# M2354 register map
File version: 1.0
Registers are 32-bit, read-write, reset 0x0 unless marked. A register's access mark holds for its fields unless they carry their own. Offsets are from the block's base; [hi:lo] are bit positions.

## SCS — SYST_SCR Register Map
Base 0xE000E000
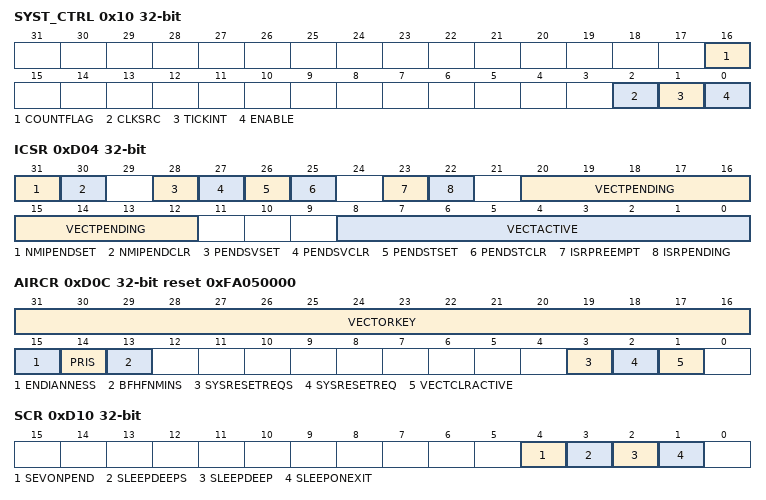
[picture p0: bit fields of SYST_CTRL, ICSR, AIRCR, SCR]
0x10 SYST_CTRL — SysTick Control and Status Register
  [16] COUNTFLAG — System Tick Counter Flag. Returns 1 if timer counted to 0 since last time this register was read. COUNTFLAG is set by a count transition from 1 to 0. COUNTFLAG is cleared on read or by a write to the Current Value register.
  [2] CLKSRC — System Tick Clock Source Selection
    0=Clock source is the (optional) external reference clock; 1=Core clock used for SysTick
  [1] TICKINT — System Tick Interrupt Enabled
    0=Counting down to 0 does not cause the SysTick exception to be pended. Software can use COUNTFLAG to determine if a count to zero has occurred; 1=Counting down to 0 will cause the SysTick exception to be pended. Clearing the SysTick current value register by a register write in software will not cause SysTick to be pended
  [0] ENABLE — System Tick Counter Enabled
    0=Counter Disabled; 1=Counter will operate in a multi-shot manner
0x14 SYST_LOAD reset not defined — SysTick Reload Value Register
  [23:0] RELOAD — System Tick Reload Value. Value to load into the Current Value register when the counter reaches 0.
0x18 SYST_VAL reset not defined — SysTick Current Value Register
  [23:0] CURRENT — System Tick Current Value. Current counter value. This is the value of the counter at the time it is sampled. The counter does not provide read-modify-write protection. The register is write-clear. A software write of any value will clear the register to 0. Unsupported bits RAZ.
0xD04 ICSR — Interrupt Control and State Register
  [31] NMIPENDSET — NMI Set-pending Bit. Write Operation: Note: If AIRCR.BFHFNMINS is 0, this bit is RAZ/WI from Non-secure state.
    0=No effect. NMI exception is not pending; 1=Changes NMI exception state to pending. NMI exception is pending
  [30] NMIPENDCLR — NMI Bit-pending Bit. Note: If AIRCR.BFHFNMINS is 0, this bit is RAZ/WI from Non-secure state.
    0=No effect; 1=Clear pending status
  [28] PENDSVSET — PendSV Set-pending Bit. Write Operation: Note: Writing 1 to this bit is the only way to set the PendSV exception state to pending.
    0=No effect. PendSV exception is not pending; 1=Changes PendSV exception state to pending. PendSV exception is pending
  [27] PENDSVCLR — PendSV Clear-pending Bit. Write Operation: Note: This is a write only bit. To clear the PENDSV bit, you must 'write 0 to PENDSVSET and write 1 to PENDSVCLR' at the same time.
    0=No effect; 1=Removes the pending state from the PendSV exception
  [26] PENDSTSET — SysTick Exception Set-pending Bit. Write Operation:
    0=No effect. SysTick exception is not pending; 1=Changes SysTick exception state to pending. SysTick exception is pending
  [25] PENDSTCLR — SysTick Exception Clear-pending Bit. Write Operation: Note: This is a write only bit. To clear the PENDST bit, you must 'write 0 to PENDSTSET and write 1 to PENDSTCLR' at the same time.
    0=No effect; 1=Removes the pending state from the SysTick exception
  [23] ISRPREEMPT ro — Interrupt Preempt Bit (Read Only). If set, a pending exception will be serviced on exit from the debug halt state.
  [22] ISRPENDING ro — Interrupt Pending Flag, Excluding NMI and Faults (Read Only)
    0=Interrupt not pending; 1=Interrupt pending
  [20:12] VECTPENDING — Number of the Highest Pended Exception
    0=no pending exceptions
  [8:0] VECTACTIVE — Number of the Current Active Exception
    0=Thread mode
0xD08 VTOR — Vector Table Offset Register
  [31:9] TBLOFF — Table Offset Bits. The vector table address for the selected Security state.
0xD0C AIRCR reset 0xFA050000 — Application Interrupt and Reset Control Register
  [31:16] VECTORKEY — Register Access Key. When writing this register, this field should be 0x05FA, otherwise the write action will be ignored. The VECTORKEY filed is used to prevent accidental write to this register from resetting the system or clearing of the exception status.
  [15] ENDIANNESS — Data Endianness
    0=Little-endian; 1=Big-endian
  [14] PRIS — Priority Secure Exceptions Bit
    0=Priority ranges of Secure and Non-secure exceptions are identical.1 = Non-secure exceptions are de-prioritized
  [13] BFHFNMINS — BusFault, HardFault, AndNMI Non-secure Enable Bit
    0=BusFault, HardFault, and NMI are Secure.1 = BusFault, Non-secure HardFault and NMI are Non-secure and exceptions can target Non-secure HardFault (Priority = -3) while Secure HardFault is secure and exception targets secure HardFault (Priority = -3)
  [3] SYSRESETREQS — System Reset Request Secure Only Bit
    0=SYSRESETREQ functionality is available to both security states.1 = SYSRESETREQ functionality is available to secure state only
  [2] SYSRESETREQ — System Reset Request Bit. Writing This Bit to 1 Will Cause A Reset Signal To Be Asserted To The Chip And Indicate A Reset Is Requested. This bit is write only and self-cleared as part of the reset sequence.
  [1] VECTCLRACTIVE — Exception Active Status Clear Bit. Setting This Bit To 1 Will Clears All Active State Information For Fixed And Configurable Exceptions. This bit is write only and can only be written when the core is halted. Note: It is the debugger's responsibility to re-initialize the stack.
0xD10 SCR — System Control Register
  [4] SEVONPEND — Send Event on Pending. When an event or interrupt enters pending state, the event signal wakes up the processor from WFE. If the processor is not waiting for an event, the event is registered and affects the next WFE. The processor also wakes up on execution of an SEV instruction or an external event.
    0=Only enabled interrupts or events can wake up the processor, while disabled interrupts are excluded; 1=Enabled events and all interrupts, including disabled interrupts, can wake up the processor
  [3] SLEEPDEEPS — SLEEPDEEP Bit Accessible Selection. Control whether the SLEEPDEEP bit is only accessible from the Secure state.
    0=The SLEEPDEEP bit is accessible from both security states; 1=The SLEEPDEEP bit behaves as RAZ/WI when accessed from the Non-secure state
  [2] SLEEPDEEP — Processor Deep Sleep and Sleep Mode Selection. Control Whether the Processor Uses Sleep Or Deep Sleep as its Low Power Mode.
    0=Sleep; 1=Deep sleep
  [1] SLEEPONEXIT — Sleep-on-exit Enable Control. This bit indicate Sleep-On-Exit when Returning from Handler Mode to Thread Mode. Setting this bit to 1 enables an interrupt driven application to avoid returning to an empty main application.
    0=Do not sleep when returning to Thread mode; 1=Enters sleep, or deep sleep, on return from an ISR to Thread mode
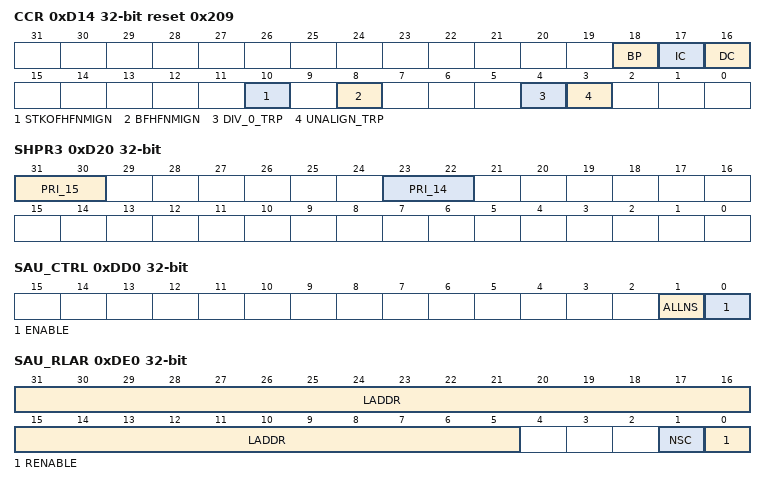
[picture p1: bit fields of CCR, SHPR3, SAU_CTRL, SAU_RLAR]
0xD14 CCR reset 0x209 — Configuration and Control Register
  [18] BP — Branch Prediction Enable Bit. This bit is RAZ/WI.
  [17] IC — Instruction Cache Enable Bit. This bit is RAZ/WI.
  [16] DC — Data Cache Enable Bit. This bit is RAZ/WI.
  [10] STKOFHFNMIGN — Stack Overflow in HardFault and NMI Ignore. This bit is RAZ/WI.
  [8] BFHFNMIGN — BusFault in HardFault or NMI Ignore. This bit is RAZ/WI.
  [4] DIV_0_TRP — Divide by Zero Trap. This bit is RAZ/WI.
  [3] UNALIGN_TRP — Unaligned Trap. This bit is RAO/WI.
0xD1C SHPR2 — System Handler Priority Register 2
  [31:30] PRI_11 — Priority of System Handler 11 - SVCall '0' denotes the highest priority and '3' denotes the lowest priority.
0xD20 SHPR3 — System Handler Priority Register 3
  [31:30] PRI_15 — Priority of System Handler 15 - SysTick '0' denotes the highest priority and '3' denotes the lowest priority.
  [23:22] PRI_14 — Priority of System Handler 14 - PendSV '0' denotes the highest priority and '3' denotes the lowest priority.
0xD24 SHCSR — System Handler Control and State Register
  [21] HARDFAULTPENDED — HardFault Exception Pended State. This bit indicates and allows modification of the pending state after HardFault exception corresponding to the selected Security state. This bit is banked between Security states. The possible values of this bit are:
    0=HardFault exception not pending for the selected Security state; 1=HardFault exception pending for the selected Security state
0xDD0 SAU_CTRL — SAU Control Register
  [1] ALLNS — All Non-secure
    0=All Memory region is marked as Secure and is not Non-secure callable; 1=All Memory region is marked as Non-secure by SAU, indicating the security attribute of all memory is defined by IDAU
  [0] ENABLE — SAU Enable Bit
    0=SAU Disabled; 1=SAU Enabled
0xDD4 SAU_TYPE ro reset 0x8
  [7:0] SREGION — SAU Regions. Indicates the number of regions implemented by the Security Attribution Unit.
0xDD8 SAU_RNR (reset mask 0xFFFFFF00) — SAU Region Number Register
  [7:0] REGION — Current Region of SAU. Indicates the SAU region accessed by SAU_RBAR and SAU_RLAR. Set a value to select the region to be configure through SAU_RBAR and SAU_RLAR. It can be set to 0 ~ the value of SAU_TYPE -1.
0xDDC SAU_RBAR (reset mask 0xF) — SAU Region Base Address Register
  [31:5] BADDR — Base Address of Currently Selected Region. The base address of the region selected by SAU_RNR. SAU region is 32-byte-aligned.
0xDE0 SAU_RLAR — SAU Region Limit Address Register
  [31:5] LADDR — Limit Address of Currently Selected Region. The limited address of the region selected by SAU_RNR. The region of the selected SAU region is [SAU_RBAR.BADDR,5'b00000] ~ [LADDR,5'b11111]
  [1] NSC — Non-secure Callable Setting Bit. Controls whether Non-secure state is permitted to execute an SG instruction from this region.
    0=Region is not Non-secure callable. If RENABLE =1, the current region is Non-secure; 1=Region is Non-secure callable. If RENABLE=1, the current region is Secure and Non-secure callable
  [0] RENABLE — Region Enable Bit. Enable or disable the currently selected region set by SAU_RNR.
    0=Disabled selected region set by SAU_RNR; 1=Enabled selected region set by SAU_RNR
